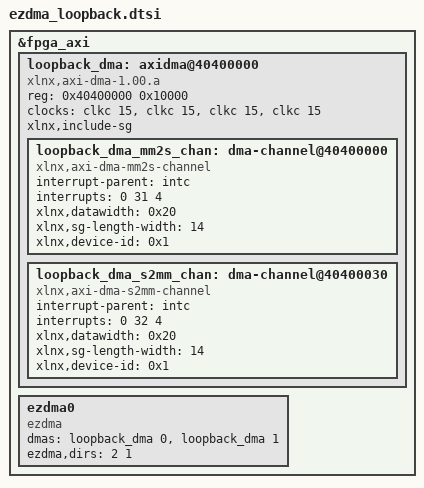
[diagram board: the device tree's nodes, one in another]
&fpga_axi {
    /* Loopback DMA setup */
    
    loopback_dma: axidma@40400000 {
        compatible = "xlnx,axi-dma-1.00.a";
        #dma-cells = <1>;
        reg = < 0x40400000 0x10000 >;
        clocks = <&clkc 15>, <&clkc 15>, <&clkc 15>, <&clkc 15>; // fclk0 from clock controller
        clock-names = "s_axi_lite_aclk", "m_axi_mm2s_aclk", "m_axi_s2mm_aclk", "m_axi_sg_aclk";
        xlnx,include-sg;

        loopback_dma_mm2s_chan: dma-channel@40400000 {
            compatible = "xlnx,axi-dma-mm2s-channel";
            interrupt-parent = <&intc>;
            interrupts = <0 31 4>;  // concat port 2
                                    // IRQ_F2P[15:0] == [91:84],[68:61]
                                    // 2 -> 63 -> 63 - 32 = 31

            xlnx,datawidth = <0x20>;        // 32-bit output
            xlnx,sg-length-width = <14>;    // Width of Buffer Length Register (configured for 20 bits)

            xlnx,device-id = <0x1>;     // what's this for?
        };

        loopback_dma_s2mm_chan: dma-channel@40400030 {
            compatible = "xlnx,axi-dma-s2mm-channel";
            interrupt-parent = <&intc>;
            interrupts = <0 32 4>;  // concat port 3 
                                    // IRQ_F2P[15:0] == [91:84],[68:61]
                                    // 3 -> 64 -> 64 - 32 = 32

            xlnx,datawidth = <0x20>;        // 32-bit output
            xlnx,sg-length-width = <14>;    // Width of Buffer Length Register (configured for 20 bits)

            xlnx,device-id = <0x1>;     // what's this for?
        };
    };

    ezdma0 {
        compatible = "ezdma";

        dmas = <&loopback_dma 0 &loopback_dma 1>;
        dma-names = "loop_tx", "loop_rx";   // used when obtaining reference to above DMA core using dma_request_slave_channel()
        ezdma,dirs = <2 1>;                 // direction of DMA channel: 1 = RX (dev->cpu), 2 = TX (cpu->dev)
    };
};  // fpga-axi
